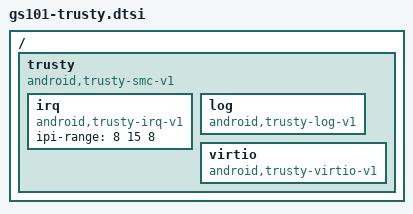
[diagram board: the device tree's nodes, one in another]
// SPDX-License-Identifier: GPL-2.0-only
/*
 * Google Slider Board device tree source
 *
 * Copyright 2019-2020 Google LLC
 */

#include <dt-bindings/interrupt-controller/arm-gic.h>

/ {
	trusty: trusty {
		compatible = "android,trusty-smc-v1";

		irq {
			compatible = "android,trusty-irq-v1";
			ipi-range = <8 15 8>;
		};

		log {
			compatible = "android,trusty-log-v1";
		};

		virtio {
			compatible = "android,trusty-virtio-v1";
		};
	};
};
